# PIC32CM1216JH01032 register map
Vendor: Microchip Technology; Series: PIC32CMJH01; File version: 0
CPU: CM0+ r0p0, little endian, MPU, no FPU, VTOR, 2 interrupt priority bits, 32 interrupts
Registers are 32-bit, read-write, reset 0x0 unless marked. A register's access mark holds for its fields unless they carry their own. Offsets are from the block's base; [hi:lo] are bit positions; {n}, {i} and the like mark numbered series.

## FREQM — Frequency Meter
Base 0x40002C00
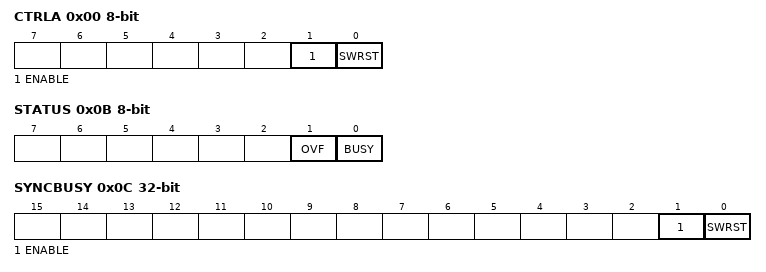
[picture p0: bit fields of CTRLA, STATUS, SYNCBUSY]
0x00 CTRLA 8-bit — Control A Register
  [1] ENABLE
  [0] SWRST — Software Reset
0x01 CTRLB 8-bit wo — Control B Register
  [0] START — Start Measurement
0x02 CFGA 16-bit — Config A register
  [7:0] REFNUM — Number of Reference Clock Cycles
0x08 INTENCLR 8-bit write-1-clears — Interrupt Enable Clear Register
  [0] DONE — Measurement Done Interrupt Enable
0x09 INTENSET 8-bit write-1-sets — Interrupt Enable Set Register
  [0] DONE — Measurement Done Interrupt Enable
0x0A INTFLAG 8-bit write-1-clears — Interrupt Flag Register
  [0] DONE — Measurement Done
0x0B STATUS 8-bit
  [1] OVF — Sticky Count Value Overflow
  [0] BUSY — FREQM Status
0x0C SYNCBUSY ro — Synchronization Busy Register
  [1] ENABLE
  [0] SWRST — Software Reset
0x10 VALUE ro — Count Value Register
  [23:0] VALUE — Measurement Value

## GCLK — Generic Clock Generator
Base 0x40001C00
0x00 CTRLA 8-bit — Control
  [0] SWRST — Software Reset
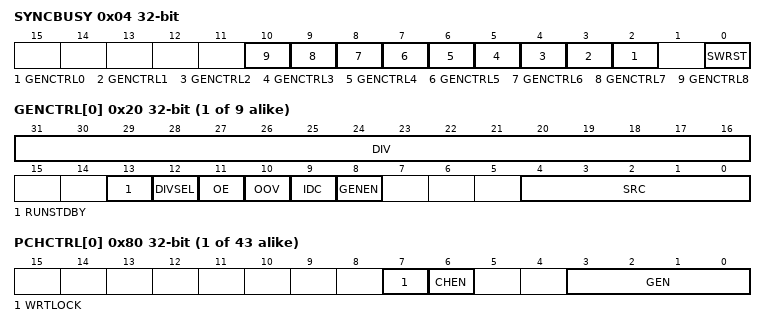
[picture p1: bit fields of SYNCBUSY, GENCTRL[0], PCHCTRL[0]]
0x04 SYNCBUSY ro — Synchronization Busy
  [n+2] GENCTRL{n} (n=0..8) — Generic Clock Generator Control {n} Synchronization Busy bit
  [0] SWRST — Software Reset Synchronization Busy bit
{0x20+4i} GENCTRL[{i}] (i=0..8) — Generic Clock Generator Control
  [31:16] DIV — Division Factor
  [13] RUNSTDBY — Run in Standby
  [12] DIVSEL — Divide Selection
    0=DIV1 (Division by GENCTRLn.DIV); 1=DIV2 (Division by 2^(GENCTRLn.DIV+1))
  [11] OE — Output Enable
  [10] OOV — Output Off Value
  [9] IDC — Improve Duty Cycle
  [8] GENEN — Generic Clock Generator Enable
  [4:0] SRC — Source Select
    0=XOSC (XOSC oscillator output); 1=GCLKIN (Generator input pad (GCLK_IO)); 2=GCLKGEN1 (Generic clock generator 1 output); 3=OSCULP32K (OSCULP32K oscillator output); 4=OSC32K (OSC32K oscillator output); 5=XOSC32K (XOSC32K oscillator output); 6=OSC48M (OSC48M oscillator output); 7=FDPLL96M (FDPLL96M output)
{0x80+4i} PCHCTRL[{i}] (i=0..42) — Peripheral Clock Control
  [7] WRTLOCK — Write Lock
  [6] CHEN — Channel Enable
  [3:0] GEN — Generic Clock Generator
    {v}=GCLK{v} (Generic clock generator {v}) (v=0..8)

## SMBIST — SRAM MBIST Interface
Base 0x42006C00
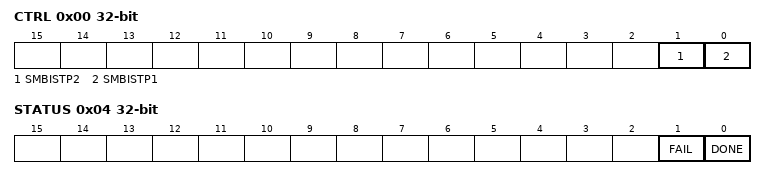
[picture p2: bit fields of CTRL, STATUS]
0x00 CTRL — Control
  [1] SMBISTP2 — SRAM MBIST Partition 2 test start
  [0] SMBISTP1 — SRAM MBIST Partition 1 test start
0x04 STATUS
  [1] FAIL, [0] DONE

## MCLK — Main Clock
Base 0x40000800
0x01 INTENCLR 8-bit write-1-clears — Interrupt Enable Clear
  [0] CKRDY — Clock Ready Interrupt Enable
0x02 INTENSET 8-bit write-1-sets — Interrupt Enable Set
  [0] CKRDY — Clock Ready Interrupt Enable
0x03 INTFLAG 8-bit reset 0x1 write-1-clears — Interrupt Flag Status and Clear
  [0] CKRDY — Clock Ready
0x04 CPUDIV 8-bit reset 0x1 — CPU Clock Division
  [7:0] CPUDIV — CPU Clock Division Factor
    1=DIV1 (Divide by 1); 2=DIV2 (Divide by 2); 4=DIV4 (Divide by 4); 8=DIV8 (Divide by 8); 16=DIV16 (Divide by 16); 32=DIV32 (Divide by 32); 64=DIV64 (Divide by 64); 128=DIV128 (Divide by 128)
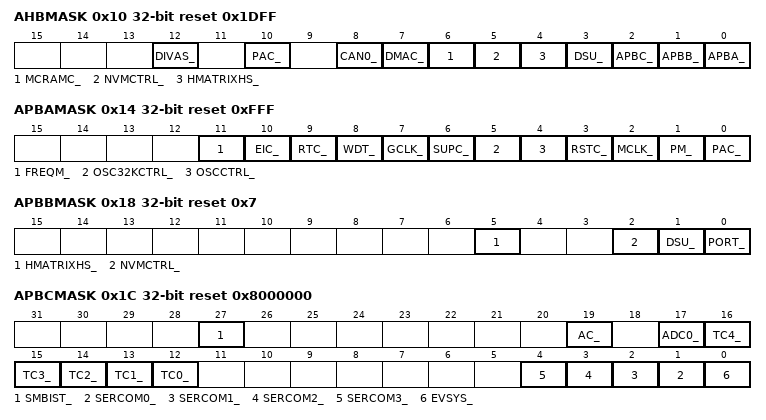
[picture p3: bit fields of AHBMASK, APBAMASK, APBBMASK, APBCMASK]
0x10 AHBMASK reset 0x1DFF
  [12] DIVAS_ — DIVAS AHB Clock Mask
  [10] PAC_ — PAC AHB Clock Mask
  [8] CAN0_ — CAN0 AHB Clock Mask
  [7] DMAC_ — DMAC AHB Clock Mask
  [6] MCRAMC_ — SRAM AHB Clock Mask
  [5] NVMCTRL_ — NVMCTRL AHB Clock Mask
  [4] HMATRIXHS_ — HMATRIXHS AHB Clock Mask
  [3] DSU_ — DSU AHB Clock Mask
  [2] APBC_ — APBC AHB Clock Mask
  [1] APBB_ — APBB AHB Clock Mask
  [0] APBA_ — APBA AHB Clock Mask
0x14 APBAMASK reset 0xFFF
  [11] FREQM_ — FREQM APB Clock Enable
  [10] EIC_ — EIC APB Clock Enable
  [9] RTC_ — RTC APB Clock Enable
  [8] WDT_ — WDT APB Clock Enable
  [7] GCLK_ — GCLK APB Clock Enable
  [6] SUPC_ — SUPC APB Clock Enable
  [5] OSC32KCTRL_ — OSC32KCTRL APB Clock Enable
  [4] OSCCTRL_ — OSCCTRL APB Clock Enable
  [3] RSTC_ — RSTC APB Clock Enable
  [2] MCLK_ — MCLK APB Clock Enable
  [1] PM_ — PM APB Clock Enable
  [0] PAC_ — PAC APB Clock Enable
0x18 APBBMASK reset 0x7
  [5] HMATRIXHS_ — HMATRIXHS APB Clock Enable
  [2] NVMCTRL_ — NVMCTRL APB Clock Enable
  [1] DSU_ — DSU APB Clock Enable
  [0] PORT_ — PORT APB Clock Enable
0x1C APBCMASK reset 0x8000000
  [27] SMBIST_ — SMBIST APB Clock Enable
  [19] AC_ — AC APB Clock Enable
  [17] ADC0_ — ADC0 APB Clock Enable
  [n+12] TC{n}_ (n=0..4) — TC{n} APB Clock Enable
  [n+1] SERCOM{n}_ (n=0..3) — SERCOM{n} APB Clock Enable
  [0] EVSYS_ — EVSYS APB Clock Enable
